# slm32x030 register map
Vendor: Keil; File version: 1.0.1
CPU: CM0 r2p1, little endian, no MPU, no FPU, 4 interrupt priority bits
Registers are 32-bit, read-write, reset 0x0 unless marked. A register's access mark holds for its fields unless they carry their own. Offsets are from the block's base; [hi:lo] are bit positions; {n}, {i} and the like mark numbered series.

## TIM1 — timer(TIMX)
Base 0x40012C00
Same registers: TIM3 0x40000400, TIM6 0x40001000, TIM7 0x40001400, TIM14 0x40002000, TIM15 0x40014000, TIM16 0x40014400, TIM17 0x40014800
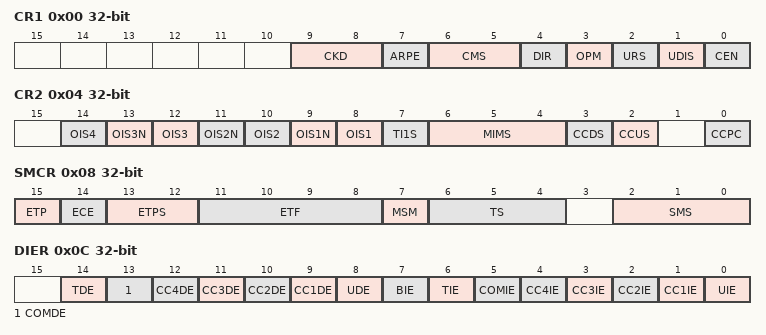
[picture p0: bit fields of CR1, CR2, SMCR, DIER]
0x00 CR1 — TIMx_CR1
  [9:8] CKD — Later Add Description
  [7] ARPE — Later Add Description
  [6:5] CMS — Later Add Description
  [4] DIR — Later Add Description
  [3] OPM — Later Add Description
  [2] URS — Later Add Description
  [1] UDIS — Later Add Description
  [0] CEN — Later Add Description
0x04 CR2 — TIMx_CR2
  [2n+6] OIS{n} (n=1..4) — Later Add Description
  [13] OIS3N — Later Add Description
  [11] OIS2N — Later Add Description
  [9] OIS1N — Later Add Description
  [7] TI1S — Later Add Description
  [6:4] MIMS — Later Add Description
  [3] CCDS — Later Add Description
  [2] CCUS — Later Add Description
  [0] CCPC — Later Add Description
0x08 SMCR — TIMx_SMCR
  [15] ETP — Later Add Description
  [14] ECE — Later Add Description
  [13:12] ETPS — Later Add Description
  [11:8] ETF — Later Add Description
  [7] MSM — Later Add Description
  [6:4] TS — Later Add Description
  [2:0] SMS — Later Add Description
0x0C DIER — TIMx_DIER
  [14] TDE — Later Add Description
  [13] COMDE — Later Add Description
  [n+8] CC{n}DE (n=1..4) — Later Add Description
  [8] UDE — Later Add Description
  [7] BIE — Later Add Description
  [6] TIE — Later Add Description
  [5] COMIE — Later Add Description
  [n] CC{n}IE (n=1..4) — Later Add Description
  [0] UIE — Later Add Description
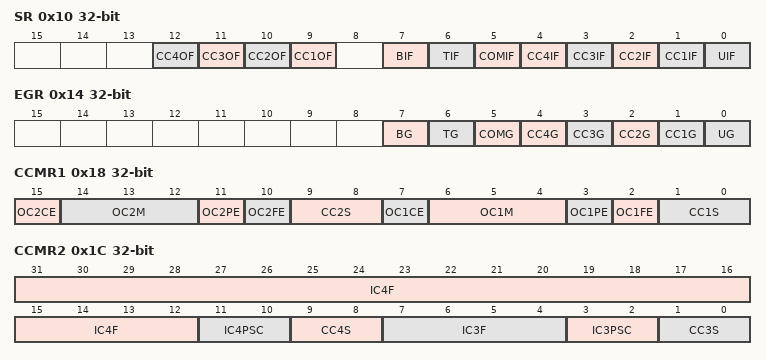
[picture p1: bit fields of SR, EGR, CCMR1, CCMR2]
0x10 SR access not given — TIMx_SR
  [n+8] CC{n}OF rw (n=1..4) — Later Add Description
  [7] BIF — Later Add Description
  [6] TIF rw — Later Add Description
  [5] COMIF rw — Later Add Description
  [n] CC{n}IF rw (n=1..4) — Later Add Description
  [0] UIF rw — Later Add Description
0x14 EGR — TIMx_EGR
  [7] BG — Later Add Description
  [6] TG — Later Add Description
  [5] COMG — Later Add Description
  [n] CC{n}G (n=1..4) — Later Add Description
  [0] UG — Later Add Description
0x18 CCMR1 — TIMx_CCMR1
  [15] OC2CE — Later Add Description
  [14:12] OC2M — Later Add Description
  [11] OC2PE — Later Add Description
  [10] OC2FE — Later Add Description
  [9:8] CC2S — Later Add Description
  [7] OC1CE — Later Add Description
  [6:4] OC1M — Later Add Description
  [3] OC1PE — Later Add Description
  [2] OC1FE — Later Add Description
  [1:0] CC1S — Later Add Description
0x1C CCMR2 — TIMx_CCMR2
  [31:12] IC4F — Later Add Description
  [11:10] IC4PSC — Later Add Description
  [9:8] CC4S — Later Add Description
  [7:4] IC3F — Later Add Description
  [3:2] IC3PSC — Later Add Description
  [1:0] CC3S — Later Add Description
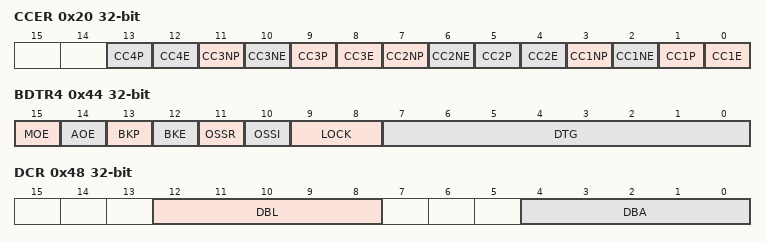
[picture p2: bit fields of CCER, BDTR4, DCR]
0x20 CCER — TIMx_CCER
  [4n-3] CC{n}P (n=1..4) — Later Add Description
  [4n-4] CC{n}E (n=1..4) — Later Add Description
  [11] CC3NP — Later Add Description
  [10] CC3NE — Later Add Description
  [7] CC2NP — Later Add Description
  [6] CC2NE — Later Add Description
  [3] CC1NP — Later Add Description
  [2] CC1NE — Later Add Description
0x24 CNT — TIMx_CNT
  [31:0] CNT — Later Add Description
0x28 PSC — TIMx_PSC
  [15:0] PSC — Later Add Description
0x2C ARR reset 0xFFFF0000 — TIMx_ARR
  [31:0] ARR — Later Add Description
0x30 RCR — TIMx_RCR
  [7:0] REP — Later Add Description
{0x30+4i} CCR{i} (i=1..4) — TIMx_CCR{i}
  [31:0] CCR{i} — Later Add Description
0x44 BDTR4 — TIMx_BDTR4
  [15] MOE — Later Add Description
  [14] AOE — Later Add Description
  [13] BKP — Later Add Description
  [12] BKE — Later Add Description
  [11] OSSR — Later Add Description
  [10] OSSI — Later Add Description
  [9:8] LOCK — Later Add Description
  [7:0] DTG — Later Add Description
0x48 DCR — TIMx_DCR
  [12:8] DBL — Later Add Description
  [4:0] DBA — Later Add Description
0x4C DMAR — TIMx_DMAR
  [31:0] DMAB — Later Add Description
